# STM32L4R9 register map
File version: 2.2
CPU: CM4 r0p1, little endian, MPU, FPU, 4 interrupt priority bits
Registers are 32-bit, read-write, reset 0x0 unless marked. A register's access mark holds for its fields unless they carry their own. Offsets are from the block's base; [hi:lo] are bit positions; lines under a group give offsets from that group; {n}, {i} and the like mark numbered series; 'fields as' and 'values as' point back to an identical list.

## CRS — Clock recovery system
Base 0x40006000
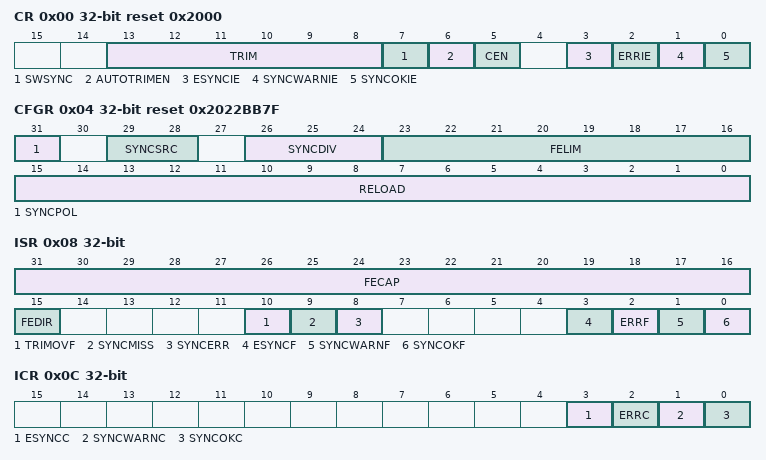
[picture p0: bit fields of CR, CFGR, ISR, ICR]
0x00 CR reset 0x2000 — control register
  [13:8] TRIM — HSI48 oscillator smooth trimming
  [7] SWSYNC — Generate software SYNC event
    1=Sync (A software sync is generated)
  [6] AUTOTRIMEN — Automatic trimming enable
    0=Disabled (Automatic trimming disabled); 1=Enabled (Automatic trimming enabled)
  [5] CEN — Frequency error counter enable
    0=Disabled (Frequency error counter disabled); 1=Enabled (Frequency error counter enabled)
  [3] ESYNCIE — Expected SYNC interrupt enable
    0=Disabled (Interrupt disabled); 1=Enabled (Interrupt enabled)
  [2] ERRIE — Synchronization or trimming error interrupt enable
    values as ESYNCIE
  [1] SYNCWARNIE — SYNC warning interrupt enable
    values as ESYNCIE
  [0] SYNCOKIE — SYNC event OK interrupt enable
    values as ESYNCIE
0x04 CFGR reset 0x2022BB7F — configuration register
  [31] SYNCPOL — SYNC polarity selection
    0=RisingEdge (SYNC active on rising edge); 1=FallingEdge (SYNC active on falling edge)
  [29:28] SYNCSRC — SYNC signal source selection
    0=GPIO_AF (GPIO AF (crs_sync_in_1) selected as SYNC signal source); 1=LSE (LSE (crs_sync_in_2) selected as SYNC signal source); 2=USB_SOF (USB SOF (crs_sync_in_3) selected as SYNC signal source)
  [26:24] SYNCDIV — SYNC divider
    0=Div1 (SYNC not divided); 1=Div2 (SYNC divided by 2); 2=Div4 (SYNC divided by 4); 3=Div8 (SYNC divided by 8); 4=Div16 (SYNC divided by 16); 5=Div32 (SYNC divided by 32); 6=Div64 (SYNC divided by 64); 7=Div128 (SYNC divided by 128)
  [23:16] FELIM — Frequency error limit
  [15:0] RELOAD — Counter reload value
0x08 ISR ro — interrupt and status register
  [31:16] FECAP — Frequency error capture
  [15] FEDIR — Frequency error direction
    0=UpCounting (Error in up-counting direction); 1=DownCounting (Error in down-counting direction)
  [10] TRIMOVF — Trimming overflow or underflow
    0=NotSignaled (Signal not set); 1=Signaled (Signal set)
  [9] SYNCMISS — SYNC missed
    0=NotSignaled (Signal not set); 1=Signaled (Signal set)
  [8] SYNCERR — SYNC error
    0=NotSignaled (Signal not set); 1=Signaled (Signal set)
  [3] ESYNCF — Expected SYNC flag
    0=NotSignaled (Signal not set); 1=Signaled (Signal set)
  [2] ERRF — Error flag
    0=NotSignaled (Signal not set); 1=Signaled (Signal set)
  [1] SYNCWARNF — SYNC warning flag
    0=NotSignaled (Signal not set); 1=Signaled (Signal set)
  [0] SYNCOKF — SYNC event OK flag
    0=NotSignaled (Signal not set); 1=Signaled (Signal set)
0x0C ICR — interrupt flag clear register
  [all] fields
    1=Clear flag
  [3] ESYNCC — Expected SYNC clear flag
  [2] ERRC — Error clear flag
  [1] SYNCWARNC — SYNC warning clear flag
  [0] SYNCOKC — SYNC event OK clear flag

## HASH — Hash processor
Base 0x50060400
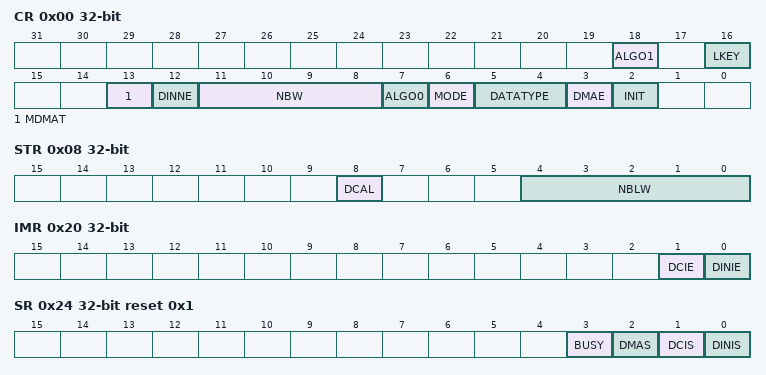
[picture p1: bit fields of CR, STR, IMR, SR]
0x00 CR access per field — control register
  [18] ALGO1 rw — ALGO
  [16] LKEY rw — Long key selection
  [13] MDMAT rw — Multiple DMA Transfers
  [12] DINNE ro — DIN not empty
  [11:8] NBW ro — Number of words already pushed
  [7] ALGO0 rw — Algorithm selection
  [6] MODE rw — Mode selection
  [5:4] DATATYPE rw — Data type selection
  [3] DMAE rw — DMA enable
  [2] INIT wo — Initialize message digest calculation
0x04 DIN — data input register
  [31:0] DATAIN — Data input
0x08 STR access per field — start register
  [8] DCAL wo — Digest calculation
  [4:0] NBLW rw — Number of valid bits in the last word of the message
{0xC+4i} HRA{i} (i=0..4) ro — HASH digest register alias {i}
  [31:0] H — H0
0x20 IMR — interrupt enable register
  [1] DCIE — Digest calculation completion interrupt enable
  [0] DINIE — Data input interrupt enable
0x24 SR access per field reset 0x1 — status register
  [3] BUSY ro — Busy bit
  [2] DMAS ro — DMA Status
  [1] DCIS rw — Digest calculation completion interrupt status
  [0] DINIS rw — Data input interrupt status
{0xF8+4i} CSR{i} (i=0..53) — HASH context swap register {i}
  [31:0] CS — CSR0
{0x310+4i} HR{i} (i=0..7) ro — HASH digest register {i}
  [31:0] H — H0

## GFXMMU — Graphic MMU
Base 0x4002C000
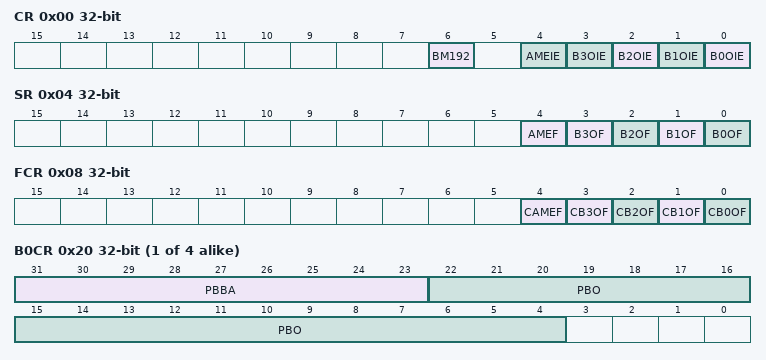
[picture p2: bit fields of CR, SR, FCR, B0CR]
0x00 CR — Graphic MMU configuration register
  [6] BM192 — 192 Block mode
  [4] AMEIE — AHB master error interrupt enable
  [n] B{n}OIE (n=0..3) — Buffer {n} overflow interrupt enable
0x04 SR ro — Graphic MMU status register
  [4] AMEF — AHB master error flag
  [n] B{n}OF (n=0..3) — Buffer {n} overflow flag
0x08 FCR wo — Graphic MMU flag clear register
  [4] CAMEF — Clear AHB master error flag
  [n] CB{n}OF (n=0..3) — Clear buffer {n} overflow flag
0x10 DVR — Graphic MMU default value register
  [31:0] DV — Default value
{0x20+4i} B{i}CR (i=0..3) — Graphic MMU buffer {i} configuration register
  [31:23] PBBA — Physical buffer base address
  [22:4] PBO — Physical buffer offset
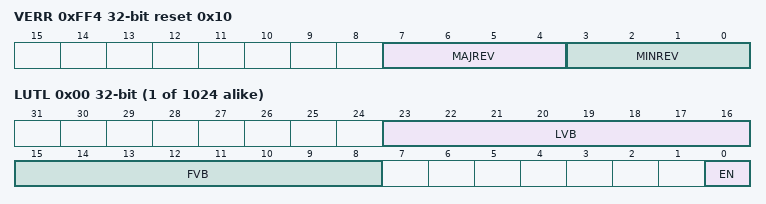
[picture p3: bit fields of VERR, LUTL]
0xFF4 VERR ro reset 0x10 — Graphic MMU version register
  [7:4] MAJREV — Major revision
  [3:0] MINREV — Minor revision
0xFF8 IPIDR ro reset 0x160061 — Graphic MMU identification register
  [31:0] ID — Identification Code
0xFFC SIDR ro reset 0xA3C5DD04 — Graphic MMU size identification register
  [31:0] SID — Size and ID
{0x1000+8i} LUT{i} (i=0..1023) group — Cluster LUT{i}, containing LUT*L, LUT*H
  0x00 LUTL — Graphic MMU LUT entry x low
    [23:16] LVB — Last Valid Block
    [15:8] FVB — First Valid Block
    [0] EN — Enable
  0x04 LUTH — Graphic MMU LUT entry x high
    [21:4] LO — Line offset

## OCTOSPIM — OctoSPI IO Manager
Base 0x50061C00
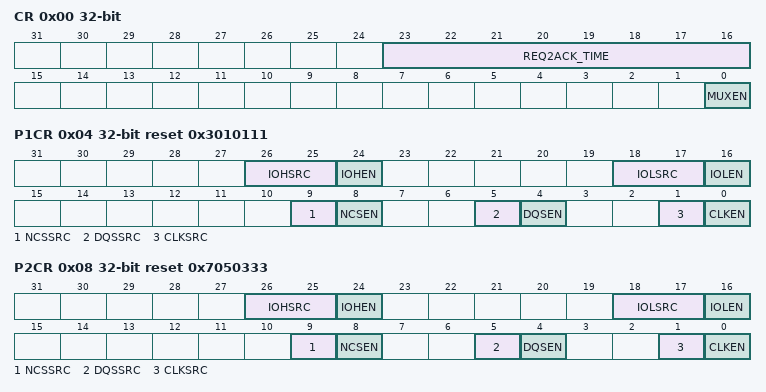
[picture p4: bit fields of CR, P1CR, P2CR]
0x00 CR access not given — configuration register
  [23:16] REQ2ACK_TIME — REQ to ACK time
  [0] MUXEN — Multiplexed mode enable
0x04 P1CR reset 0x3010111 — OctoSPI IO Manager Port 1 Configuration Register
  [26:25] IOHSRC — Source for Port
  [24] IOHEN — Enable for Port n
  [18:17] IOLSRC — Source for Port
  [16] IOLEN — Enable for Port
  [9] NCSSRC — CS Source for Port
  [8] NCSEN — CS Enable for Port
  [5] DQSSRC — DQS Source for Port
  [4] DQSEN — DQS Enable for Port
  [1] CLKSRC — CLK/CLK Source for Port
  [0] CLKEN — CLK/CLK Enable for Port
0x08 P2CR reset 0x7050333 — OctoSPI IO Manager Port 2 Configuration Register
  fields as P1CR
